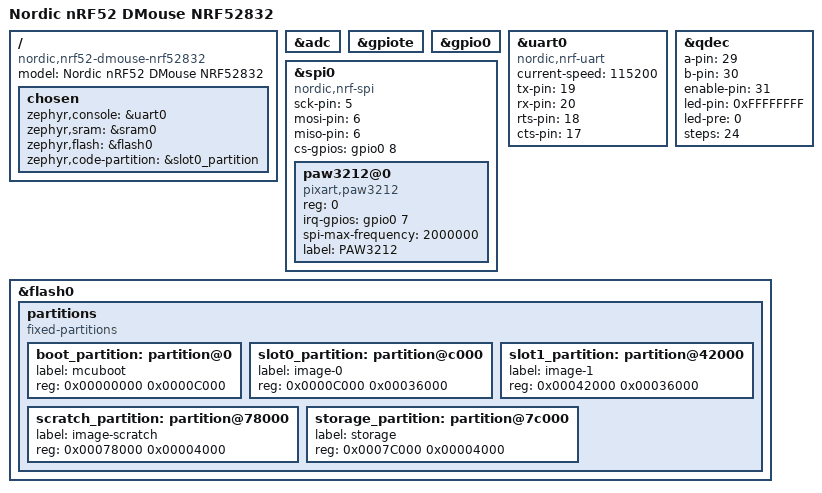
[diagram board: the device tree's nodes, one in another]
/*
 * Copyright (c) 2019 Nordic Semiconductor ASA
 *
 * SPDX-License-Identifier: LicenseRef-BSD-5-Clause-Nordic
 */

/dts-v1/;
#include <nordic/nrf52832_qfaa.dtsi>

/ {
	model = "Nordic nRF52 DMouse NRF52832";
	compatible = "nordic,nrf52-dmouse-nrf52832";

	chosen {
		zephyr,console = &uart0;
		zephyr,sram = &sram0;
		zephyr,flash = &flash0;
		zephyr,code-partition = &slot0_partition;
	};
};

&adc {
	status = "okay";
};

&gpiote {
	status = "okay";
};

&gpio0 {
	status = "okay";
};

&uart0 {
	status = "okay";
	compatible = "nordic,nrf-uart";
	current-speed = <115200>;
	tx-pin = <19>;
	rx-pin = <20>;
	rts-pin = <18>;
	cts-pin = <17>;
};

&qdec {
	status = "okay";
	a-pin = <29>;
	b-pin = <30>;
	enable-pin = <31>;
	led-pin = <0xFFFFFFFF>;
	led-pre = <0>;
	steps = <24>;
};

&spi0 {
	compatible = "nordic,nrf-spi";
	status = "okay";
	sck-pin = <5>;
	mosi-pin = <6>;
	miso-pin = <6>;
	cs-gpios = <&gpio0 8 0>;

	paw3212@0 {
		compatible = "pixart,paw3212";
		reg = <0>;
		irq-gpios = <&gpio0 7 0>;
		spi-max-frequency = <2000000>;
		label = "PAW3212";
	};
};

&flash0 {
	/*
	 * For more information, see:
	 * http://docs.zephyrproject.org/latest/guides/dts/index.html#flash-partitions
	 */
	partitions {
		compatible = "fixed-partitions";
		#address-cells = <1>;
		#size-cells = <1>;

		boot_partition: partition@0 {
			label = "mcuboot";
			reg = <0x00000000 0x0000C000>;
		};
		slot0_partition: partition@c000 {
			label = "image-0";
			reg = <0x0000C000 0x00036000>;
		};
		slot1_partition: partition@42000 {
			label = "image-1";
			reg = <0x00042000 0x00036000>;
		};
		scratch_partition: partition@78000 {
			label = "image-scratch";
			reg = <0x00078000 0x00004000>;
		};
		storage_partition: partition@7c000 {
			label = "storage";
			reg = <0x0007C000 0x00004000>;
		};
	};
};
